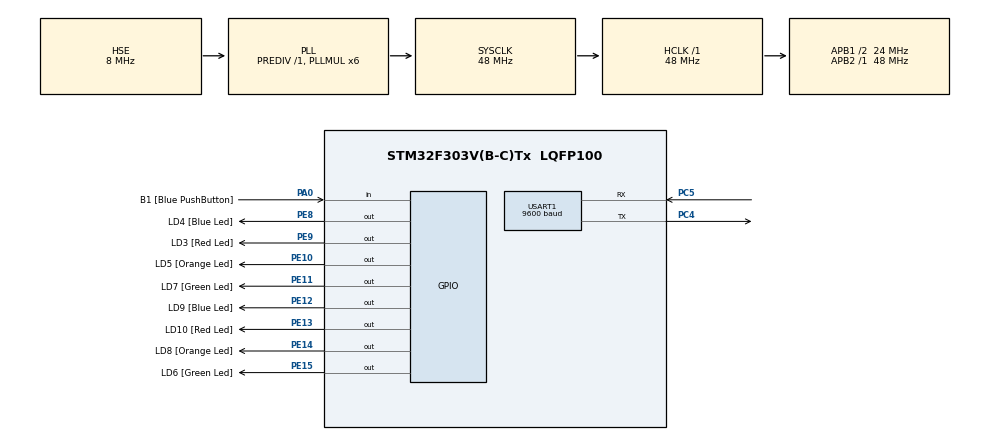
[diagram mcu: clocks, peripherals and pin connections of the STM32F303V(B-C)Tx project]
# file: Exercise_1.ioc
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Mcu.Family=STM32F3
Mcu.Name=STM32F303V(B-C)Tx
Mcu.Package=LQFP100
NVIC.PriorityGroup=NVIC_PRIORITYGROUP_0
NVIC.USART1_IRQn=true\:0\:0\:false\:false\:true\:true\:false
PA0.GPIO_Label=B1 [Blue PushButton]
PA0.Signal=GPIO_Input
PA13.GPIO_Label=SWDIO
PA13.Mode=Serial_Wire
PA13.Signal=SYS_JTMS-SWDIO
PA14.GPIO_Label=SWCLK
PA14.Mode=Serial_Wire
PA14.Signal=SYS_JTCK-SWCLK
PB3.GPIO_Label=SWO
PB3.Signal=SYS_JTDO-TRACESWO
PC4.Mode=Asynchronous
PC4.Signal=USART1_TX
PC5.Mode=Asynchronous
PC5.Signal=USART1_RX
PE10.GPIO_Label=LD5 [Orange Led]
PE10.Signal=GPIO_Output
PE11.GPIO_Label=LD7 [Green Led]
PE11.Signal=GPIO_Output
PE12.GPIO_Label=LD9 [Blue Led]
PE12.Signal=GPIO_Output
PE13.GPIO_Label=LD10 [Red Led]
PE13.Signal=GPIO_Output
PE14.GPIO_Label=LD8 [Orange Led]
PE14.Signal=GPIO_Output
PE15.GPIO_Label=LD6 [Green Led]
PE15.Signal=GPIO_Output
PE8.GPIO_Label=LD4 [Blue Led]
PE8.Signal=GPIO_Output
PE9.GPIO_Label=LD3 [Red Led]
PE9.Signal=GPIO_Output
PF0-OSC_IN.GPIO_Label=OSC_IN
PF0-OSC_IN.Mode=HSE-External-Clock-Source
PF0-OSC_IN.Signal=RCC_OSC_IN
ProjectManager.HeapSize=0x200
ProjectManager.StackSize=0x400
ProjectManager.TargetToolchain=MDK-ARM V5
RCC.AHBFreq_Value=48000000
RCC.APB1CLKDivider=RCC_HCLK_DIV2
RCC.APB1Freq_Value=24000000
RCC.APB1TimFreq_Value=48000000
RCC.APB2Freq_Value=48000000
RCC.APB2TimFreq_Value=48000000
RCC.CortexFreq_Value=48000000
RCC.HCLKFreq_Value=48000000
RCC.HSE_VALUE=8000000
RCC.HSI_VALUE=8000000
RCC.LSE_VALUE=32768
RCC.PLLMUL=RCC_PLL_MUL6
RCC.PLLSourceVirtual=RCC_PLLSOURCE_HSE
RCC.SYSCLKFreq_VALUE=48000000
RCC.SYSCLKSourceVirtual=RCC_SYSCLKSOURCE_PLLCLK
RCC.USBFreq_Value=48000000
USART1.BaudRate=9600
USART1.VirtualMode-Asynchronous=VM_ASYNC
board=STM32F3DISCOVERY

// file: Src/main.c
/* USER CODE BEGIN Header */
/**
  ******************************************************************************
  * @file           : main.c
  * @brief          : Main program body
  ******************************************************************************
  * @attention
  *
  * <h2><center>&copy; Copyright (c) 2019 STMicroelectronics.
  * All rights reserved.</center></h2>
  *
  * This software component is licensed by ST under BSD 3-Clause license,
  * the "License"; You may not use this file except in compliance with the
  * License. You may obtain a copy of the License at:
  *                        opensource.org/licenses/BSD-3-Clause
  *
  ******************************************************************************
  */
/* USER CODE END Header */

#include "main.h"
#include "usart.h"
#include "gpio.h"

/* USER CODE BEGIN Includes */
	#include <string.h>
/* USER CODE END Includes */

void SystemClock_Config(void);

int main(void)
{

  /* MCU Configuration--------------------------------------------------------*/

  /* Reset of all peripherals, Initializes the Flash interface and the Systick. */
  HAL_Init();

  /* Configure the system clock */
  SystemClock_Config();

  /* Initialize all configured peripherals */
  MX_GPIO_Init();
  MX_USART1_UART_Init();
  /* USER CODE BEGIN 2 */

	uint8_t msg[] = {"Initialisation completed\n\r"};
	HAL_UART_Transmit_IT(&huart1, msg, strlen((const char *)msg));

  /* USER CODE END 2 */

  /* Infinite loop */
  /* USER CODE BEGIN WHILE */

	// buffer
	uint8_t ch = 0;

  while (1)
  {
    /* USER CODE END WHILE */

    /* USER CODE BEGIN 3 */
	  if (HAL_UART_Receive_IT(&huart1, &ch, 1) == HAL_OK) {
		  // received data
		  switch (ch) {
			  case '\r':
				  HAL_UART_Transmit_IT(&huart1, "\n\r", 2);
				  break;
			  default:
				  HAL_UART_Transmit_IT(&huart1, &ch, 1);
		  }
	  }
  }
  /* USER CODE END 3 */
}

void SystemClock_Config(void)
{
  RCC_OscInitTypeDef RCC_OscInitStruct = {0};
  RCC_ClkInitTypeDef RCC_ClkInitStruct = {0};
  RCC_PeriphCLKInitTypeDef PeriphClkInit = {0};

  /** Initializes the CPU, AHB and APB busses clocks
  */
  RCC_OscInitStruct.OscillatorType = RCC_OSCILLATORTYPE_HSE;
  RCC_OscInitStruct.HSEState = RCC_HSE_BYPASS;
  RCC_OscInitStruct.HSEPredivValue = RCC_HSE_PREDIV_DIV1;
  RCC_OscInitStruct.HSIState = RCC_HSI_ON;
  RCC_OscInitStruct.PLL.PLLState = RCC_PLL_ON;
  RCC_OscInitStruct.PLL.PLLSource = RCC_PLLSOURCE_HSE;
  RCC_OscInitStruct.PLL.PLLMUL = RCC_PLL_MUL6;
  if (HAL_RCC_OscConfig(&RCC_OscInitStruct) != HAL_OK)
  {
    Error_Handler();
  }
  /** Initializes the CPU, AHB and APB busses clocks
  */
  RCC_ClkInitStruct.ClockType = RCC_CLOCKTYPE_HCLK|RCC_CLOCKTYPE_SYSCLK
                              |RCC_CLOCKTYPE_PCLK1|RCC_CLOCKTYPE_PCLK2;
  RCC_ClkInitStruct.SYSCLKSource = RCC_SYSCLKSOURCE_PLLCLK;
  RCC_ClkInitStruct.AHBCLKDivider = RCC_SYSCLK_DIV1;
  RCC_ClkInitStruct.APB1CLKDivider = RCC_HCLK_DIV2;
  RCC_ClkInitStruct.APB2CLKDivider = RCC_HCLK_DIV1;

  if (HAL_RCC_ClockConfig(&RCC_ClkInitStruct, FLASH_LATENCY_1) != HAL_OK)
  {
    Error_Handler();
  }
  PeriphClkInit.PeriphClockSelection = RCC_PERIPHCLK_USART1;
  PeriphClkInit.Usart1ClockSelection = RCC_USART1CLKSOURCE_PCLK2;
  if (HAL_RCCEx_PeriphCLKConfig(&PeriphClkInit) != HAL_OK)
  {
    Error_Handler();
  }
}

void Error_Handler(void)
{
}

/************************ (C) COPYRIGHT STMicroelectronics *****END OF FILE****/
